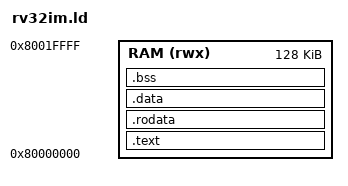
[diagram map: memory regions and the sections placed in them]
/* Linker script for rv32im bare metal */
ENTRY(_start)

MEMORY
{
    RAM (rwx) : ORIGIN = 0x80000000, LENGTH = 128K
}

SECTIONS
{
    .text : {
        *(.text._start)
        *(.text .text.*)
    } > RAM

    .rodata : {
        *(.rodata .rodata.*)
    } > RAM

    .data : {
        *(.data .data.*)
    } > RAM

    .bss : {
        *(.bss .bss.*)
    } > RAM

    /DISCARD/ : {
        *(.eh_frame)
        *(.eh_frame_hdr)
        *(.comment)
    }
}
